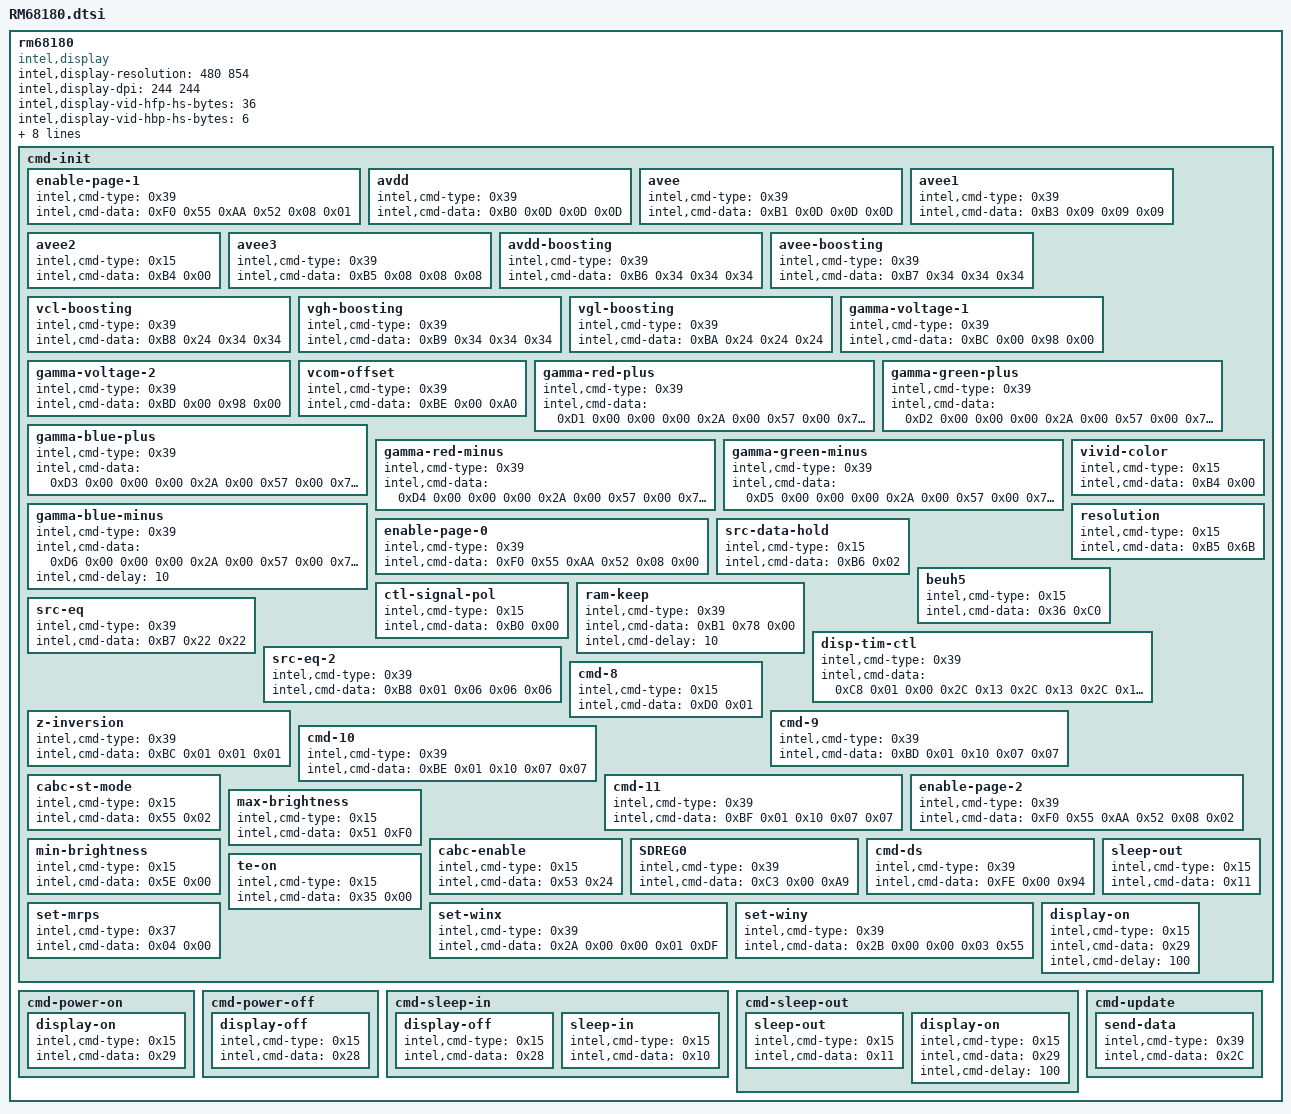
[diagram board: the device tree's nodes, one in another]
	rm68180 {
		compatible = "intel,display";
		intel,display-resolution= <480 854>;
		intel,display-dpi= <244 244>;

		/* MIPI-DSI video mode settings */
		intel,display-vid-hfp-hs-bytes = <36>;
		intel,display-vid-hbp-hs-bytes = <6>;
		intel,display-vid-hsa-hs-bytes = <6>;
		intel,display-vid-vfp-lines = <7>;
		intel,display-vid-vbp-lines = <3>;
		intel,display-vid-vsa-lines = <2>;

		intel,display-vid-mode = "burst";
		intel,display-vid-id = <0>;
		intel,display-vid-pixel = "24packed";

		intel,display-reset = <1 1 0 2 1 10>;

		cmd-init {
			enable-page-1 {
				intel,cmd-type = <0x39>;
				intel,cmd-data = <0xF0 0x55 0xAA 0x52 0x08 0x01>;
			};
			avdd {
				intel,cmd-type = <0x39>;
				intel,cmd-data = <0xB0 0x0D 0x0D 0x0D>;
			};
			avee {
				intel,cmd-type = <0x39>;
				intel,cmd-data = <0xB1 0x0D 0x0D 0x0D>;
			};
			avee1 {
				intel,cmd-type = <0x39>;
				intel,cmd-data = <0xB3 0x09 0x09 0x09>;
			};
			avee2 {
				intel,cmd-type = <0x15>;
				intel,cmd-data = <0xB4 0x00>;
			};
			avee3 {
				intel,cmd-type = <0x39>;
				intel,cmd-data = <0xB5 0x08 0x08 0x08>;
			};
			avdd-boosting {
				intel,cmd-type = <0x39>;
				intel,cmd-data = <0xB6 0x34 0x34 0x34>;
			};
			avee-boosting {
				intel,cmd-type = <0x39>;
				intel,cmd-data = <0xB7 0x34 0x34 0x34>;
			};
			vcl-boosting {
				intel,cmd-type = <0x39>;
				intel,cmd-data = <0xB8 0x24 0x34 0x34>;
			};
			vgh-boosting {
				intel,cmd-type = <0x39>;
				intel,cmd-data = <0xB9 0x34 0x34 0x34>;
			};
			vgl-boosting {
				intel,cmd-type = <0x39>;
				intel,cmd-data = <0xBA 0x24 0x24 0x24>;
			};
			gamma-voltage-1 {
				intel,cmd-type = <0x39>;
				intel,cmd-data = <0xBC 0x00 0x98 0x00>;
			};
			gamma-voltage-2 {
				intel,cmd-type = <0x39>;
				intel,cmd-data = <0xBD 0x00 0x98 0x00>;
			};
			vcom-offset {
				intel,cmd-type = <0x39>;
				intel,cmd-data = <0xBE 0x00 0xA0>;
			};
			gamma-red-plus {
				intel,cmd-type = <0x39>;
				intel,cmd-data = <0xD1
					0x00 0x00 0x00 0x2A 0x00 0x57 0x00 0x75 0x00 0x8D
					0x00 0xB1 0x00 0xCF 0x00 0xFD 0x01 0x22 0x01 0x5D
					0x01 0x8C 0x01 0xD6 0x02 0x14 0x02 0x15 0x02 0x4F
					0x02 0x8D 0x02 0xB2 0x02 0xE2 0x03 0x01 0x03 0x28
					0x03 0x40 0x03 0x5B 0x03 0x6B 0x03 0x7A	0x03 0x84
					0x03 0x85>;
			};
			gamma-green-plus {
				intel,cmd-type = <0x39>;
				intel,cmd-data = <0xD2
					0x00 0x00 0x00 0x2A 0x00 0x57 0x00 0x75 0x00 0x8D
					0x00 0xB1 0x00 0xCF 0x00 0xFD 0x01 0x22 0x01 0x5D
					0x01 0x8C 0x01 0xD6 0x02 0x14 0x02 0x15 0x02 0x4F
					0x02 0x8D 0x02 0xB2 0x02 0xE2 0x03 0x01 0x03 0x28
					0x03 0x40 0x03 0x5B 0x03 0x6B 0x03 0x7A 0x03 0x84
					0x03 0x85>;
			};
			gamma-blue-plus {
				intel,cmd-type = <0x39>;
				intel,cmd-data = <0xD3
					0x00 0x00 0x00 0x2A 0x00 0x57 0x00 0x75 0x00 0x8D
					0x00 0xB1 0x00 0xCF 0x00 0xFD 0x01 0x22 0x01 0x5D
					0x01 0x8C 0x01 0xD6 0x02 0x14 0x02 0x15 0x02 0x4F
					0x02 0x8D 0x02 0xB2 0x02 0xE2 0x03 0x01 0x03 0x28
					0x03 0x40 0x03 0x5B 0x03 0x6B 0x03 0x7A 0x03 0x84
					0x03 0x85>;
			};
			gamma-red-minus {
				intel,cmd-type = <0x39>;
				intel,cmd-data = <0xD4
					0x00 0x00 0x00 0x2A 0x00 0x57 0x00 0x75 0x00 0x8D
					0x00 0xB1 0x00 0xCF 0x00 0xFD 0x01 0x22 0x01 0x5D
					0x01 0x8C 0x01 0xD6 0x02 0x14 0x02 0x15 0x02 0x4F
					0x02 0x8D 0x02 0xB2 0x02 0xE2 0x03 0x01 0x03 0x28
					0x03 0x40 0x03 0x5B 0x03 0x6B 0x03 0x7A 0x03 0x84
					0x03 0x85>;
			};
			gamma-green-minus {
				intel,cmd-type = <0x39>;
				intel,cmd-data = <0xD5
					0x00 0x00 0x00 0x2A 0x00 0x57 0x00 0x75 0x00 0x8D
					0x00 0xB1 0x00 0xCF 0x00 0xFD 0x01 0x22 0x01 0x5D
					0x01 0x8C 0x01 0xD6 0x02 0x14 0x02 0x15 0x02 0x4F
					0x02 0x8D 0x02 0xB2 0x02 0xE2 0x03 0x01 0x03 0x28
					0x03 0x40 0x03 0x5B 0x03 0x6B 0x03 0x7A 0x03 0x84
					0x03 0x85>;
			};
			gamma-blue-minus {
				intel,cmd-type = <0x39>;
				intel,cmd-data = <0xD6
					0x00 0x00 0x00 0x2A 0x00 0x57 0x00 0x75 0x00 0x8D
					0x00 0xB1 0x00 0xCF 0x00 0xFD 0x01 0x22 0x01 0x5D
					0x01 0x8C 0x01 0xD6 0x02 0x14 0x02 0x15 0x02 0x4F
					0x02 0x8D 0x02 0xB2 0x02 0xE2 0x03 0x01 0x03 0x28
					0x03 0x40 0x03 0x5B 0x03 0x6B 0x03 0x7A 0x03 0x84
					0x03 0x85>;
				intel,cmd-delay = <10>;
			};
			enable-page-0 {
				intel,cmd-type = <0x39>;
				intel,cmd-data = <0xF0 0x55 0xAA 0x52 0x08 0x00>;
			};
			vivid-color{
				intel,cmd-type = <0x15>;
				intel,cmd-data = <0xB4 0x00>;
			};
			resolution{
				intel,cmd-type = <0x15>;
				intel,cmd-data = <0xB5 0x6B>;
			};
			src-data-hold{
				intel,cmd-type = <0x15>;
				intel,cmd-data = <0xB6 0x02>;
			};
			beuh5{
				intel,cmd-type = <0x15>;
				intel,cmd-data = <0x36 0xC0>;
			};
			ctl-signal-pol{
				intel,cmd-type = <0x15>;
				intel,cmd-data = <0xB0 0x00>;
			};
			ram-keep{
				intel,cmd-type = <0x39>;
				intel,cmd-data = <0xB1 0x78 0x00>;
				intel,cmd-delay = <10>;
			};
			src-eq{
				intel,cmd-type = <0x39>;
				intel,cmd-data = <0xB7 0x22 0x22>;
			};
			disp-tim-ctl{
				intel,cmd-type = <0x39>;
				intel,cmd-data = <0xC8 0x01 0x00 0x2C 0x13 0x2C 0x13 0x2C 0x13 0x2C 0x13 0x3F 0x3F 0x3F 0x3F 0x3F 0x3F 0x3F 0x3F>;
			};
			src-eq-2{
				intel,cmd-type = <0x39>;
				intel,cmd-data = <0xB8 0x01 0x06 0x06 0x06>;
			};
			z-inversion{
				intel,cmd-type = <0x39>;
				intel,cmd-data = <0xBC 0x01 0x01 0x01>;
			};
			cmd-8{
				intel,cmd-type = <0x15>;
				intel,cmd-data = <0xD0 0x01>;
			};
			cmd-9{
				intel,cmd-type = <0x39>;
				intel,cmd-data = <0xBD 0x01 0x10 0x07 0x07>;
			};
			cmd-10{
				intel,cmd-type = <0x39>;
				intel,cmd-data = <0xBE 0x01 0x10 0x07 0x07>;
			};
			cmd-11{
				intel,cmd-type = <0x39>;
				intel,cmd-data = <0xBF 0x01 0x10 0x07 0x07>;
			};
			enable-page-2 {
				intel,cmd-type = <0x39>;
				intel,cmd-data = <0xF0 0x55 0xAA 0x52 0x08 0x02>;
			};
			cabc-st-mode{
				intel,cmd-type = <0x15>;
				intel,cmd-data = <0x55 0x02>;
			};
			max-brightness{
				intel,cmd-type = <0x15>;
				intel,cmd-data = <0x51 0xF0>;
			};
			min-brightness{
				intel,cmd-type = <0x15>;
				intel,cmd-data = <0x5E 0x00>;
			};
			cabc-enable{
				intel,cmd-type = <0x15>;
				intel,cmd-data = <0x53 0x24>;
			};
			SDREG0{
				intel,cmd-type = <0x39>;
				intel,cmd-data = <0xC3 0x00 0xA9>;
			};
			cmd-ds{
				intel,cmd-type = <0x39>;
				intel,cmd-data = <0xFE 0x00 0x94>;
			};
			te-on{
				intel,cmd-type = <0x15>;
				intel,cmd-data = <0x35 0x00>;
			};
			set-winx{
				intel,cmd-type = <0x39>;
				intel,cmd-data = <0x2A 0x00 0x00 0x01 0xDF>;
			};
			set-winy{
				intel,cmd-type = <0x39>;
				intel,cmd-data = <0x2B 0x00 0x00 0x03 0x55>;
			};
			set-mrps{
				intel,cmd-type = <0x37>;
				intel,cmd-data = <0x04 0x00>;
			};
			sleep-out{
				intel,cmd-type = <0x15>;
				intel,cmd-data = <0x11>;
			};
			display-on{
				intel,cmd-type = <0x15>;
				intel,cmd-data = <0x29>;
				intel,cmd-delay = <100>;
			};
		};

		cmd-power-on {
			display-on{
				intel,cmd-type = <0x15>;
				intel,cmd-data = <0x29>;
			};
		};

		cmd-power-off {
			display-off{
				intel,cmd-type = <0x15>;
				intel,cmd-data = <0x28>;
			};
		};

		cmd-sleep-in {
			display-off{
				intel,cmd-type = <0x15>;
				intel,cmd-data = <0x28>;
			};
			sleep-in{
				intel,cmd-type = <0x15>;
				intel,cmd-data = <0x10>;
			};
		};

		cmd-sleep-out {
			sleep-out{
				intel,cmd-type = <0x15>;
				intel,cmd-data = <0x11>;
			};
			display-on{
				intel,cmd-type = <0x15>;
				intel,cmd-data = <0x29>;
				intel,cmd-delay = <100>;
			};
		};

		cmd-update {
			send-data {
				intel,cmd-type = <0x39>;
				intel,cmd-data = <0x2C>;
			};
		};


	};
